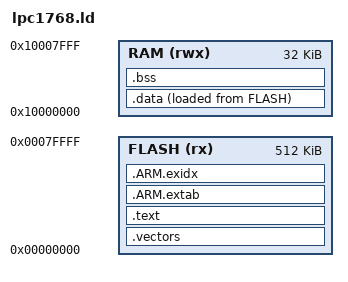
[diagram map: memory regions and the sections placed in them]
/* SPDX-License-Identifier: MIT */
ENTRY(Reset_Handler)
MEMORY {
  FLASH (rx) : ORIGIN = 0x00000000, LENGTH = 512K
  RAM (rwx) : ORIGIN = 0x10000000, LENGTH = 32K
}
_estack = ORIGIN(RAM) + LENGTH(RAM);
SECTIONS {
  .vectors : { KEEP(*(.vectors)) } > FLASH
  .text : { *(.text*) *(.rodata*) . = ALIGN(4); } > FLASH
  .ARM.extab : { *(.ARM.extab*) } > FLASH
  .ARM.exidx : { *(.ARM.exidx*) } > FLASH
  .data : { . = ALIGN(4); _sdata = .; *(.data*) . = ALIGN(4); _edata = .; } > RAM AT> FLASH
  _sidata = LOADADDR(.data);
  .bss (NOLOAD) : { . = ALIGN(4); _sbss = .; *(.bss*) *(COMMON) . = ALIGN(4); _ebss = .; } > RAM
  _heap_start = ALIGN(_ebss, 8);
  _heap_end = ORIGIN(RAM) + LENGTH(RAM) - 8K;
  ASSERT(_heap_start <= _heap_end, "Static data leaves no room for the reserved 8 KiB stack")
  /DISCARD/ : { *(.comment) *(.note*) }
}
